# STM32L4x6_v1r1 register map
File version: 1.1
Registers are 32-bit, read-write, reset 0x0 unless marked. A register's access mark holds for its fields unless they carry their own. Offsets are from the block's base; [hi:lo] are bit positions; {n}, {i} and the like mark numbered series; 'fields as' and 'values as' point back to an identical list.

## DCMI — Digital camera interface
Base 0x50050000
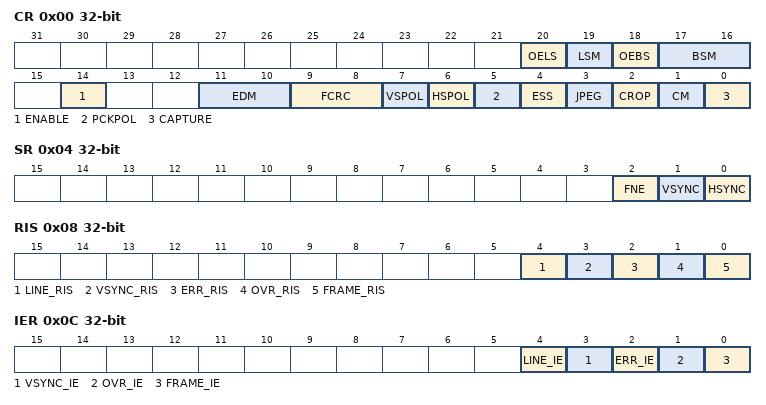
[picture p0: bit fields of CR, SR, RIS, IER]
0x00 CR — control register 1
  [20] OELS — Odd/Even Line Select (Line Select Start)
  [19] LSM — Line Select mode
  [18] OEBS — Odd/Even Byte Select (Byte Select Start)
  [17:16] BSM — Byte Select mode
  [14] ENABLE — DCMI enable
  [11:10] EDM — Extended data mode
  [9:8] FCRC — Frame capture rate control
  [7] VSPOL — Vertical synchronization polarity
  [6] HSPOL — Horizontal synchronization polarity
  [5] PCKPOL — Pixel clock polarity
  [4] ESS — Embedded synchronization select
  [3] JPEG — JPEG format
  [2] CROP — Crop feature
  [1] CM — Capture mode
  [0] CAPTURE — Capture enable
0x04 SR ro — status register
  [2] FNE — FIFO not empty
  [1] VSYNC
  [0] HSYNC
0x08 RIS ro — raw interrupt status register
  [4] LINE_RIS — Line raw interrupt status
  [3] VSYNC_RIS — VSYNC raw interrupt status
  [2] ERR_RIS — Synchronization error raw interrupt status
  [1] OVR_RIS — Overrun raw interrupt status
  [0] FRAME_RIS — Capture complete raw interrupt status
0x0C IER — interrupt enable register
  [4] LINE_IE — Line interrupt enable
  [3] VSYNC_IE — VSYNC interrupt enable
  [2] ERR_IE — Synchronization error interrupt enable
  [1] OVR_IE — Overrun interrupt enable
  [0] FRAME_IE — Capture complete interrupt enable
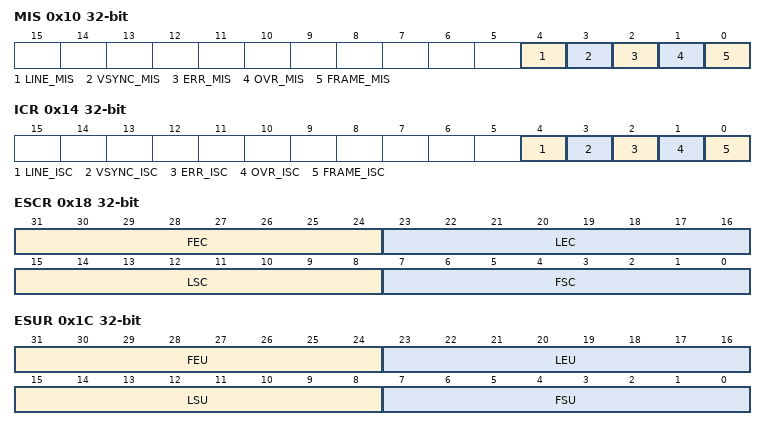
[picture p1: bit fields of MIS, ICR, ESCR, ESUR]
0x10 MIS ro — masked interrupt status register
  [4] LINE_MIS — Line masked interrupt status
  [3] VSYNC_MIS — VSYNC masked interrupt status
  [2] ERR_MIS — Synchronization error masked interrupt status
  [1] OVR_MIS — Overrun masked interrupt status
  [0] FRAME_MIS — Capture complete masked interrupt status
0x14 ICR wo — interrupt clear register
  [4] LINE_ISC — line interrupt status clear
  [3] VSYNC_ISC — Vertical synch interrupt status clear
  [2] ERR_ISC — Synchronization error interrupt status clear
  [1] OVR_ISC — Overrun interrupt status clear
  [0] FRAME_ISC — Capture complete interrupt status clear
0x18 ESCR — embedded synchronization code register
  [31:24] FEC — Frame end delimiter code
  [23:16] LEC — Line end delimiter code
  [15:8] LSC — Line start delimiter code
  [7:0] FSC — Frame start delimiter code
0x1C ESUR — embedded synchronization unmask register
  [31:24] FEU — Frame end delimiter unmask
  [23:16] LEU — Line end delimiter unmask
  [15:8] LSU — Line start delimiter unmask
  [7:0] FSU — Frame start delimiter unmask
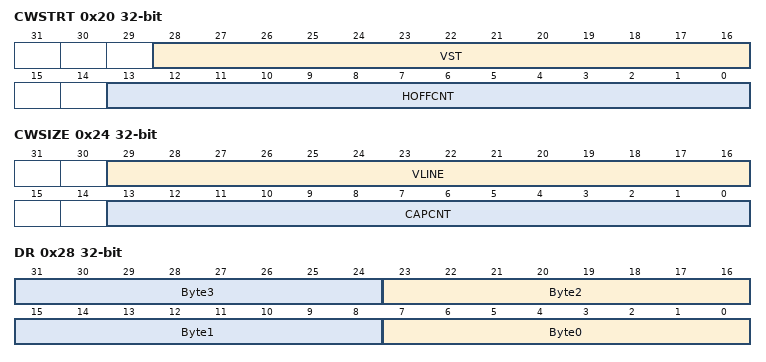
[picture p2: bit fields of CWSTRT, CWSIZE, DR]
0x20 CWSTRT — crop window start
  [28:16] VST — Vertical start line count
  [13:0] HOFFCNT — Horizontal offset count
0x24 CWSIZE — crop window size
  [29:16] VLINE — Vertical line count
  [13:0] CAPCNT — Capture count
0x28 DR ro — data register
  [8n+7:8n] Byte{n} (n=0..3) — Data byte {n}

## HASH — Hash processor
Base 0x50060400
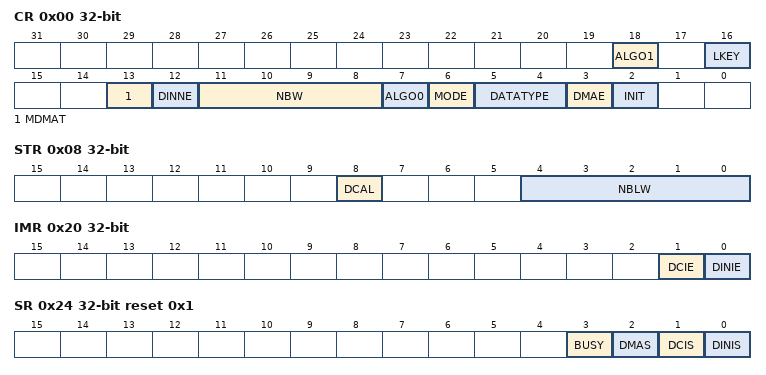
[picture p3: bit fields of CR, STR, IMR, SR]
0x00 CR access per field — control register
  [18] ALGO1 rw — ALGO
  [16] LKEY rw — Long key selection
  [13] MDMAT rw — Multiple DMA Transfers
  [12] DINNE ro — DIN not empty
  [11:8] NBW ro — Number of words already pushed
  [7] ALGO0 rw — Algorithm selection
  [6] MODE rw — Mode selection
  [5:4] DATATYPE rw — Data type selection
  [3] DMAE rw — DMA enable
  [2] INIT wo — Initialize message digest calculation
0x04 DIN — data input register
  [31:0] DATAIN — Data input
0x08 STR access per field — start register
  [8] DCAL wo — Digest calculation
  [4:0] NBLW rw — Number of valid bits in the last word of the message
0x0C HR0 ro — digest registers
  [31:0] H0
0x20 IMR — interrupt enable register
  [1] DCIE — Digest calculation completion interrupt enable
  [0] DINIE — Data input interrupt enable
0x24 SR access per field reset 0x1 — status register
  [3] BUSY ro — Busy bit
  [2] DMAS ro — DMA Status
  [1] DCIS rw — Digest calculation completion interrupt status
  [0] DINIS rw — Data input interrupt status
{0xF8+4i} CSR{i} (i=0..53) — context swap registers
0x310 HASH_HR0 ro — HASH digest register
  [31:0] H0
{0x310+4i} HASH_HR{i} ro (i=1..7) — read-only
  [31:0] H{i}

## DMA2D — DMA2D controller
Base 0x4002B000
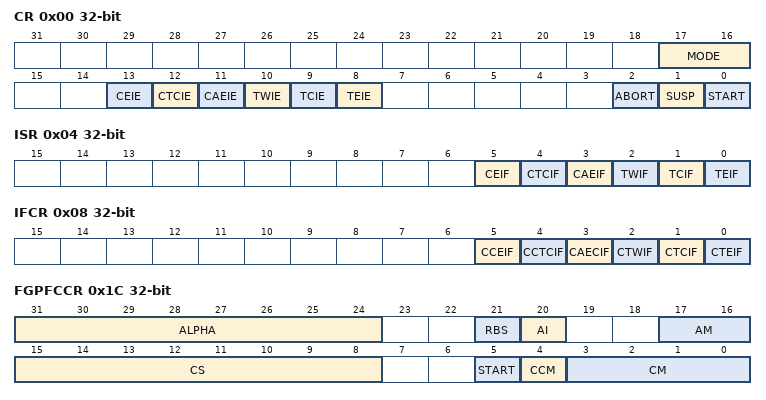
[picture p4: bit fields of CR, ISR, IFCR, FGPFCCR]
0x00 CR — control register
  [17:16] MODE — DMA2D mode
  [13] CEIE — Configuration Error Interrupt Enable
  [12] CTCIE — CLUT transfer complete interrupt enable
  [11] CAEIE — CLUT access error interrupt enable
  [10] TWIE — Transfer watermark interrupt enable
  [9] TCIE — Transfer complete interrupt enable
  [8] TEIE — Transfer error interrupt enable
  [2] ABORT
  [1] SUSP — Suspend
  [0] START
0x04 ISR ro — Interrupt Status Register
  [5] CEIF — Configuration error interrupt flag
  [4] CTCIF — CLUT transfer complete interrupt flag
  [3] CAEIF — CLUT access error interrupt flag
  [2] TWIF — Transfer watermark interrupt flag
  [1] TCIF — Transfer complete interrupt flag
  [0] TEIF — Transfer error interrupt flag
0x08 IFCR — interrupt flag clear register
  [5] CCEIF — Clear configuration error interrupt flag
  [4] CCTCIF — Clear CLUT transfer complete interrupt flag
  [3] CAECIF — Clear CLUT access error interrupt flag
  [2] CTWIF — Clear transfer watermark interrupt flag
  [1] CTCIF — Clear transfer complete interrupt flag
  [0] CTEIF — Clear Transfer error interrupt flag
0x0C FGMAR — foreground memory address register
  [31:0] MA — Memory address
0x10 FGOR — foreground offset register
  [13:0] LO — Line offset
0x14 BGMAR — background memory address register
  [31:0] MA — Memory address
0x18 BGOR — background offset register
  [13:0] LO — Line offset
0x1C FGPFCCR — foreground PFC control register
  [31:24] ALPHA — Alpha value
  [21] RBS — Red Blue Swap
  [20] AI — Alpha Inverted
  [17:16] AM — Alpha mode
  [15:8] CS — CLUT size
  [5] START
  [4] CCM — CLUT color mode
  [3:0] CM — Color mode
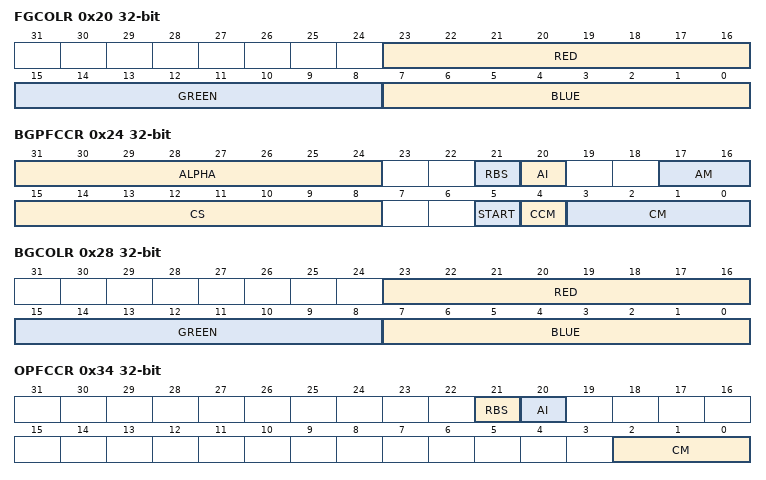
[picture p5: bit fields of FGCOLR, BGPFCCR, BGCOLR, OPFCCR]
0x20 FGCOLR — foreground color register
  [23:16] RED — Red Value
  [15:8] GREEN — Green Value
  [7:0] BLUE — Blue Value
0x24 BGPFCCR — background PFC control register
  [31:24] ALPHA — Alpha value
  [21] RBS — Red Blue Swap
  [20] AI — Alpha Inverted
  [17:16] AM — Alpha mode
  [15:8] CS — CLUT size
  [5] START
  [4] CCM — CLUT Color mode
  [3:0] CM — Color mode
0x28 BGCOLR — background color register
  fields as FGCOLR
0x2C FGCMAR — foreground CLUT memory address register
  [31:0] MA — Memory Address
0x30 BGCMAR — background CLUT memory address register
  [31:0] MA — Memory address
0x34 OPFCCR — output PFC control register
  [21] RBS — Red Blue Swap
  [20] AI — Alpha Inverted
  [2:0] CM — Color mode
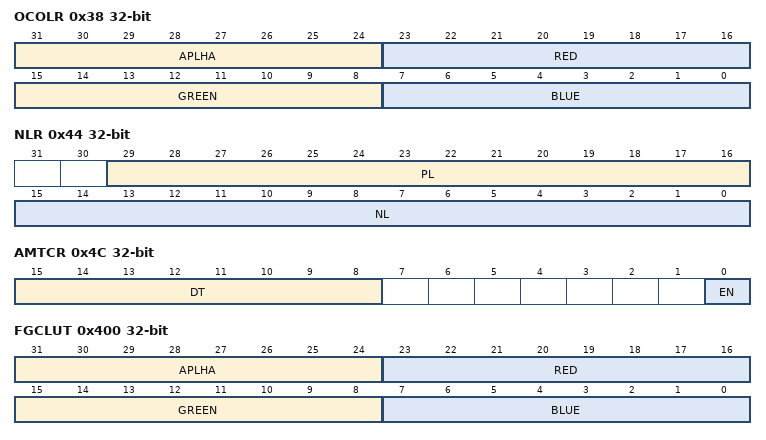
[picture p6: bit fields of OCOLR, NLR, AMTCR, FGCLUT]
0x38 OCOLR — output color register
  [31:24] APLHA — Alpha Channel Value
  [23:16] RED — Red Value
  [15:8] GREEN — Green Value
  [7:0] BLUE — Blue Value
0x3C OMAR — output memory address register
  [31:0] MA — Memory Address
0x40 OOR — output offset register
  [13:0] LO — Line Offset
0x44 NLR — number of line register
  [29:16] PL — Pixel per lines
  [15:0] NL — Number of lines
0x48 LWR — line watermark register
  [15:0] LW — Line watermark
0x4C AMTCR — AHB master timer configuration register
  [15:8] DT — Dead Time
  [0] EN — Enable
0x400 FGCLUT
  [31:24] APLHA, [23:16] RED, [15:8] GREEN, [7:0] BLUE
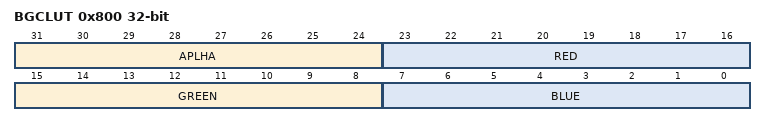
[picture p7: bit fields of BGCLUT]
0x800 BGCLUT
  [31:24] APLHA, [23:16] RED, [15:8] GREEN, [7:0] BLUE
